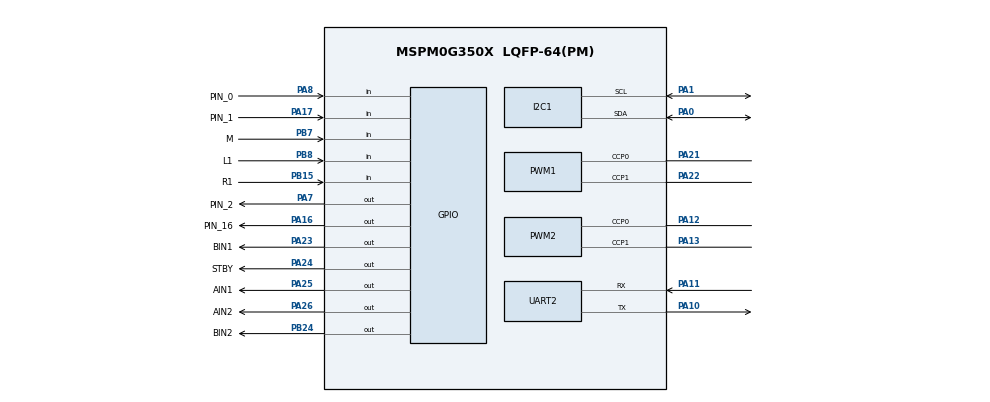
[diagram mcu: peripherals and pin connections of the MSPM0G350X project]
/**
 * @cliArgs --device "MSPM0G350X" --package "LQFP-64(PM)" --part "Default" --product "mspm0_sdk@2.01.00.03"
 * @versions {"tool":"1.20.0+3587"}
 */

/**
 * Import the modules used in this configuration.
 */
const GPIO    = scripting.addModule("/ti/driverlib/GPIO", {}, false);
const GPIO1   = GPIO.addInstance();
const GPIO2   = GPIO.addInstance();
const GPIO3   = GPIO.addInstance();
const GPIO4   = GPIO.addInstance();
const GPIO5   = GPIO.addInstance();
const I2C     = scripting.addModule("/ti/driverlib/I2C", {}, false);
const I2C1    = I2C.addInstance();
const PWM     = scripting.addModule("/ti/driverlib/PWM", {}, false);
const PWM1    = PWM.addInstance();
const PWM2    = PWM.addInstance();
const SYSCTL  = scripting.addModule("/ti/driverlib/SYSCTL");
const SYSTICK = scripting.addModule("/ti/driverlib/SYSTICK");
const TIMER   = scripting.addModule("/ti/driverlib/TIMER", {}, false);
const TIMER1  = TIMER.addInstance();
const UART    = scripting.addModule("/ti/driverlib/UART", {}, false);
const UART1   = UART.addInstance();
const UART2   = UART.addInstance();

/**
 * Write custom configuration values to the imported modules.
 */
GPIO1.$name                          = "LED";
GPIO1.associatedPins[0].$name        = "PIN_16";
GPIO1.associatedPins[0].assignedPort = "PORTA";
GPIO1.associatedPins[0].assignedPin  = "16";
GPIO1.associatedPins[0].pin.$assign  = "PA16";

const Board = scripting.addModule("/ti/driverlib/Board", {}, false);

GPIO2.$name                         = "MOTOR";
GPIO2.associatedPins.create(5);
GPIO2.associatedPins[0].$name       = "AIN1";
GPIO2.associatedPins[0].pin.$assign = "PA25";
GPIO2.associatedPins[1].$name       = "AIN2";
GPIO2.associatedPins[1].pin.$assign = "PA26";
GPIO2.associatedPins[2].$name       = "BIN1";
GPIO2.associatedPins[2].pin.$assign = "PA23";
GPIO2.associatedPins[3].$name       = "BIN2";
GPIO2.associatedPins[3].pin.$assign = "PB24";
GPIO2.associatedPins[4].$name       = "STBY";
GPIO2.associatedPins[4].pin.$assign = "PA24";

GPIO3.$name                         = "Grayscale_Sensor";
GPIO3.associatedPins.create(3);
GPIO3.associatedPins[0].$name       = "L1";
GPIO3.associatedPins[0].direction   = "INPUT";
GPIO3.associatedPins[0].pin.$assign = "PB8";
GPIO3.associatedPins[1].$name       = "M";
GPIO3.associatedPins[1].direction   = "INPUT";
GPIO3.associatedPins[1].pin.$assign = "PB7";
GPIO3.associatedPins[2].$name       = "R1";
GPIO3.associatedPins[2].direction   = "INPUT";
GPIO3.associatedPins[2].pin.$assign = "PB15";

GPIO4.$name                         = "GPIO_MOTOR";
GPIO4.associatedPins.create(2);
GPIO4.associatedPins[0].$name       = "PIN_1";
GPIO4.associatedPins[0].direction   = "INPUT";
GPIO4.associatedPins[0].interruptEn = true;
GPIO4.associatedPins[0].polarity    = "RISE";
GPIO4.associatedPins[0].pin.$assign = "PA17";
GPIO4.associatedPins[1].$name       = "PIN_0";
GPIO4.associatedPins[1].direction   = "INPUT";
GPIO4.associatedPins[1].interruptEn = true;
GPIO4.associatedPins[1].polarity    = "RISE";
GPIO4.associatedPins[1].pin.$assign = "PA8";

GPIO5.$name                          = "GPIO_GRP_0";
GPIO5.associatedPins[0].$name        = "PIN_2";
GPIO5.associatedPins[0].initialValue = "SET";
GPIO5.associatedPins[0].pin.$assign  = "PA7";

I2C1.$name                           = "I2C_0";
I2C1.basicEnableController           = true;
I2C1.basicControllerStandardBusSpeed = "Fast";
I2C1.peripheral.$assign              = "I2C0";
I2C1.peripheral.sdaPin.$assign       = "PA0";
I2C1.peripheral.sclPin.$assign       = "PA1";
I2C1.sdaPinConfig.$name              = "ti_driverlib_gpio_GPIOPinGeneric3";
I2C1.sclPinConfig.$name              = "ti_driverlib_gpio_GPIOPinGeneric7";

PWM1.$name                              = "PWM_SERVO";
PWM1.clockDivider                       = 8;
PWM1.clockPrescale                      = 40;
PWM1.timerCount                         = 2000;
PWM1.peripheral.$assign                 = "TIMG6";
PWM1.peripheral.ccp0Pin.$assign         = "PA21";
PWM1.peripheral.ccp1Pin.$assign         = "PA22";
PWM1.PWM_CHANNEL_0.$name                = "ti_driverlib_pwm_PWMTimerCC2";
PWM1.PWM_CHANNEL_1.$name                = "ti_driverlib_pwm_PWMTimerCC3";
PWM1.ccp0PinConfig.direction            = scripting.forceWrite("OUTPUT");
PWM1.ccp0PinConfig.hideOutputInversion  = scripting.forceWrite(false);
PWM1.ccp0PinConfig.onlyInternalResistor = scripting.forceWrite(false);
PWM1.ccp0PinConfig.passedPeripheralType = scripting.forceWrite("Digital");
PWM1.ccp0PinConfig.$name                = "ti_driverlib_gpio_GPIOPinGeneric4";
PWM1.ccp1PinConfig.direction            = scripting.forceWrite("OUTPUT");
PWM1.ccp1PinConfig.hideOutputInversion  = scripting.forceWrite(false);
PWM1.ccp1PinConfig.onlyInternalResistor = scripting.forceWrite(false);
PWM1.ccp1PinConfig.passedPeripheralType = scripting.forceWrite("Digital");
PWM1.ccp1PinConfig.$name                = "ti_driverlib_gpio_GPIOPinGeneric5";

PWM2.timerCount                         = 3200;
PWM2.$name                              = "PWM_MOTOR";
PWM2.pwmMode                            = "EDGE_ALIGN_UP";
PWM2.peripheral.$assign                 = "TIMG0";
PWM2.peripheral.ccp0Pin.$assign         = "PA12";
PWM2.peripheral.ccp1Pin.$assign         = "PA13";
PWM2.PWM_CHANNEL_0.$name                = "ti_driverlib_pwm_PWMTimerCC4";
PWM2.PWM_CHANNEL_1.$name                = "ti_driverlib_pwm_PWMTimerCC0";
PWM2.ccp0PinConfig.direction            = scripting.forceWrite("OUTPUT");
PWM2.ccp0PinConfig.hideOutputInversion  = scripting.forceWrite(false);
PWM2.ccp0PinConfig.onlyInternalResistor = scripting.forceWrite(false);
PWM2.ccp0PinConfig.passedPeripheralType = scripting.forceWrite("Digital");
PWM2.ccp0PinConfig.$name                = "ti_driverlib_gpio_GPIOPinGeneric6";
PWM2.ccp1PinConfig.direction            = scripting.forceWrite("OUTPUT");
PWM2.ccp1PinConfig.hideOutputInversion  = scripting.forceWrite(false);
PWM2.ccp1PinConfig.onlyInternalResistor = scripting.forceWrite(false);
PWM2.ccp1PinConfig.passedPeripheralType = scripting.forceWrite("Digital");
PWM2.ccp1PinConfig.$name                = "ti_driverlib_gpio_GPIOPinGeneric2";

SYSCTL.forceDefaultClkConfig = true;

SYSTICK.period = 3200;

TIMER1.$name                       = "TIMER_0";
TIMER1.event1ControllerInterruptEn = ["ZERO_EVENT"];
TIMER1.interrupts                  = ["ZERO"];
TIMER1.timerMode                   = "PERIODIC";
TIMER1.timerClkDiv                 = 8;
TIMER1.timerClkPrescale            = 32;
TIMER1.timerPeriod                 = "10 ms";
TIMER1.timerStartTimer             = true;
TIMER1.peripheral.$assign          = "TIMG7";

UART1.enabledInterrupts                = ["RX"];
UART1.$name                            = "UART_BLUETOOTH";
UART1.peripheral.$assign               = "UART2";
UART1.txPinConfig.direction            = scripting.forceWrite("OUTPUT");
UART1.txPinConfig.hideOutputInversion  = scripting.forceWrite(false);
UART1.txPinConfig.onlyInternalResistor = scripting.forceWrite(false);
UART1.txPinConfig.passedPeripheralType = scripting.forceWrite("Digital");
UART1.txPinConfig.$name                = "ti_driverlib_gpio_GPIOPinGeneric0";
UART1.rxPinConfig.hideOutputInversion  = scripting.forceWrite(false);
UART1.rxPinConfig.onlyInternalResistor = scripting.forceWrite(false);
UART1.rxPinConfig.passedPeripheralType = scripting.forceWrite("Digital");
UART1.rxPinConfig.$name                = "ti_driverlib_gpio_GPIOPinGeneric1";

UART2.$name                            = "UART_VISION";
UART2.targetBaudRate                   = 115200;
UART2.enabledInterrupts                = ["RX"];
UART2.peripheral.$assign               = "UART0";
UART2.peripheral.rxPin.$assign         = "PA11";
UART2.peripheral.txPin.$assign         = "PA10";
UART2.txPinConfig.$name                = "ti_driverlib_gpio_GPIOPinGeneric8";
UART2.txPinConfig.direction            = scripting.forceWrite("OUTPUT");
UART2.txPinConfig.hideOutputInversion  = scripting.forceWrite(false);
UART2.txPinConfig.onlyInternalResistor = scripting.forceWrite(false);
UART2.txPinConfig.passedPeripheralType = scripting.forceWrite("Digital");
UART2.rxPinConfig.$name                = "ti_driverlib_gpio_GPIOPinGeneric9";
UART2.rxPinConfig.hideOutputInversion  = scripting.forceWrite(false);
UART2.rxPinConfig.onlyInternalResistor = scripting.forceWrite(false);
UART2.rxPinConfig.passedPeripheralType = scripting.forceWrite("Digital");

/**
 * Pinmux solution for unlocked pins/peripherals. This ensures that minor changes to the automatic solver in a future
 * version of the tool will not impact the pinmux you originally saw.  These lines can be completely deleted in order to
 * re-solve from scratch.
 */
Board.peripheral.$suggestSolution          = "DEBUGSS";
Board.peripheral.swclkPin.$suggestSolution = "PA20";
Board.peripheral.swdioPin.$suggestSolution = "PA19";
SYSCTL.peripheral.$suggestSolution         = "SYSCTL";
UART1.peripheral.rxPin.$suggestSolution    = "PB16";
UART1.peripheral.txPin.$suggestSolution    = "PB17";
